AUTOSAR XML (schema 4-2-2)
package /ComponentTypes
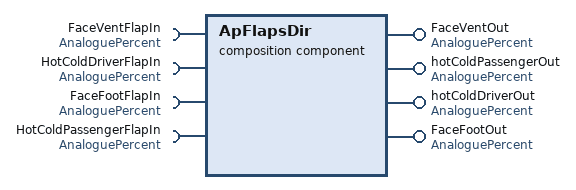
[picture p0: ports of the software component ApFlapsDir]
  composition sw component type ApFlapsDir
    4 x require port, all with required-interface=AnaloguePercent:
      FaceVentFlapIn
      HotColdDriverFlapIn
      FaceFootFlapIn
      HotColdPassengerFlapIn
    4 x provide port, all with provided-interface=AnaloguePercent:
      FaceVentOut
      hotColdPassengerOut
      hotColdDriverOut
      FaceFootOut
    component Flaps: type=FlapController
    delegate Flaps.HotColdPassOut <-> outer port hotColdPassengerOut
    delegate Flaps.HotColdDriverOut <-> outer port hotColdDriverOut
    delegate Flaps.FaceFootOut <-> outer port FaceFootOut
    delegate Flaps.FaceVentOut <-> outer port FaceVentOut
    delegate Flaps.FaceFoot <-> outer port FaceFootFlapIn
    delegate Flaps.HotColdDri <-> outer port HotColdDriverFlapIn
    delegate Flaps.HotColdPass <-> outer port HotColdPassengerFlapIn
    delegate Flaps.FaceVent <-> outer port FaceVentFlapIn
